# STM32C562 register map
File version: 2.1.0
CPU: CM33 r0p4, little endian, MPU, FPU, 4 interrupt priority bits
Registers are 32-bit, read-write, reset 0x0 unless marked. A register's access mark holds for its fields unless they carry their own. Offsets are from the block's base; [hi:lo] are bit positions; {n}, {i} and the like mark numbered series; 'fields as' and 'values as' point back to an identical list.

## RAMCFG — RAMCFG address block description
Base 0x40026000
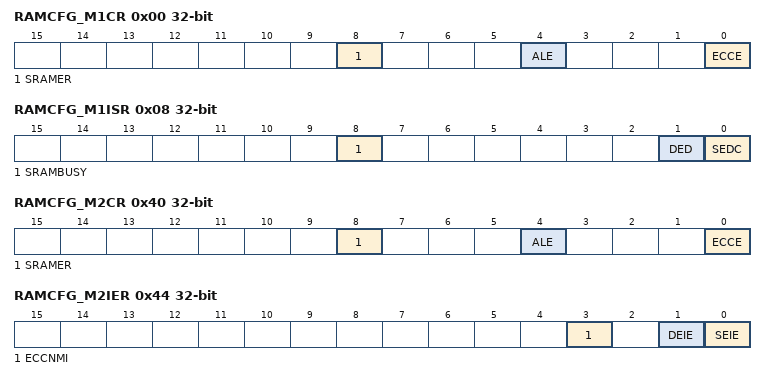
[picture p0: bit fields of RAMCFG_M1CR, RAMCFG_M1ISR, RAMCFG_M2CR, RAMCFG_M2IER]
0x00 RAMCFG_M1CR (reset mask 0xFFFFFFF0) — RAMCFG memory 1 control register
  [8] SRAMER — SRAM erase
    0=No erase operation on going; 1=Erase operation on going
  [4] ALE — Address latch enable
    0=Failing address not stored in the SRAMx ECC single/double error address registers; 1=Failing address stored in the SRAMx ECC single/double error address registers
  [0] ECCE — ECC enable.
    0=ECC disabled; 1=ECC enabled
0x08 RAMCFG_M1ISR ro — RAMCFG memory 1 interrupt status register
  [8] SRAMBUSY — SRAM busy with erase operation
    0=No erase operation on going; 1=Erase operation on going
  [1] DED — ECC double error detected
    0=No double error; 1=Double error detected
  [0] SEDC — ECC single error detected and corrected
    0=No single error; 1=Single error detected and corrected
0x28 RAMCFG_M1ERKEYR wo — RAMCFG memory 1 erase key register
  [7:0] ERASEKEY — Erase write protection key
0x40 RAMCFG_M2CR (reset mask 0xFFFFFFF0) — RAMCFG memory 2 control register
  fields as RAMCFG_M1CR
0x44 RAMCFG_M2IER — RAMCFG memory 2 interrupt enable register
  [3] ECCNMI — Double error NMI
    0=NMI not generated in case of ECC double error; 1=NMI generated in case of ECC double error
  [1] DEIE — ECC double error interrupt enable
    0=Double error interrupt disabled; 1=Double error interrupt enabled
  [0] SEIE — ECC single error interrupt enable
    0=Single error interrupt disabled; 1=Single error interrupt enabled
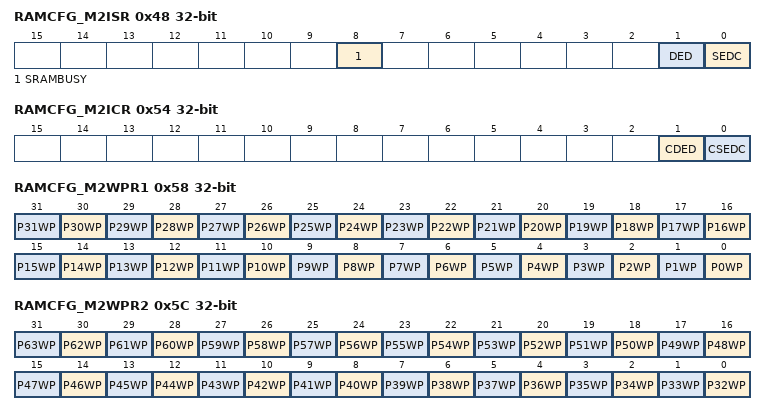
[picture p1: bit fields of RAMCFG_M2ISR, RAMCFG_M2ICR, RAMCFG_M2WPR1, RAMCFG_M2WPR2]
0x48 RAMCFG_M2ISR ro — RAMCFG memory 2 interrupt status register
  fields as RAMCFG_M1ISR
0x4C RAMCFG_M2SEAR ro — RAMCFG memory 2 ECC single error address register
  [31:0] ESEA — ECC single error address
0x50 RAMCFG_M2DEAR ro — RAMCFG memory 2 ECC double error address register
  [31:0] EDEA — ECC double error address
0x54 RAMCFG_M2ICR — RAMCFG memory 2 interrupt clear register 2
  [1] CDED — Clear ECC double error detected
  [0] CSEDC — Clear ECC single error detected and corrected
0x58 RAMCFG_M2WPR1 — RAMCFG memory 2 write protection register 1
  [all] fields
    0=Write protection of SRAM2 1-Kbyte page y is disabled; 1=Write protection of SRAM2 1-Kbyte page y is enabled
  [n] P{n}WP (n=0..31) — SRAM2 1-Kbyte page y write protection
0x5C RAMCFG_M2WPR2 — RAMCFG memory 2 write protection register 2
  [all] fields
    values as the fields of RAMCFG_M2WPR1
  [n-32] P{n}WP (n=32..63) — SRAM2 1-Kbyte page y write protection
0x64 RAMCFG_M2ECCKEYR wo — RAMCFG memory 2 ECC key register
  [7:0] ECCKEY — ECC write protection key
0x68 RAMCFG_M2ERKEYR wo — RAMCFG memory 2 erase key register
  [7:0] ERASEKEY — Erase write protection key

## SBS — SBS address block description
Base 0x44000400
0x10 SBS_HDPLCR reset 0xB4 — SBS temporal isolation control register
  [7:0] INCR_HDPL — increment HDPL value
    180=no increment; 106=recommended value to increment HDPL level by one
0x14 SBS_HDPLSR ro reset not defined — SBS temporal isolation status register
  [7:0] HDPL — temporal isolation level
    81=HDPL1, hide protection level to be used to execute and protect an immutable root of trust (IROT) stage; 138=HDPL2, hide protection level to be used to execute and protect an updatable Root of Trust (UROT) stage; 111=HDPL3, hide protection level to be used to execute the application
0x104 SBS_FPUIMR reset 0x1F — SBS FPU interrupt mask register
  [5:0] FPU_IE — FPU interrupt enable
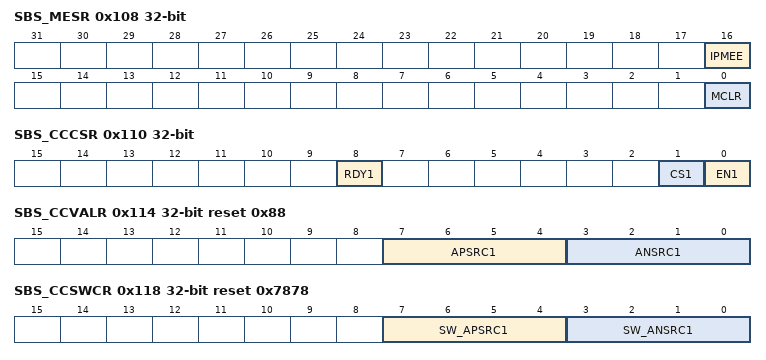
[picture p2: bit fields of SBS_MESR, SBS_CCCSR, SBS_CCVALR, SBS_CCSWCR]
0x108 SBS_MESR (reset mask 0xFFF0FFF0) — SBS memory erase status register
  [16] IPMEE — ICACHE erase status
    0=ICACHE erase ongoing; 1=ICACHE erase ended
  [0] MCLR — Device memories erase status
    0=memory erase ongoing if not yet cleared by software; 1=memory erase done
0x110 SBS_CCCSR — SBS compensation cell for I/Os control and status register
  [8] RDY1 ro — VDDIO compensation cell ready flag
    0=VDDIO compensation cell not ready; 1=VDDIO compensation cell ready (code value provided by the cell can be used)
  [1] CS1 — code selection for VDDIO power rail (reset value set to 1)
    0=Code from the cell (available in the SBS_CCVR); 1=Code from SBS_CCCR
  [0] EN1 — enable compensation cell for VDDIO power rail
    0=I/O compensation cell disabled; 1=I/O compensation cell enabled
0x114 SBS_CCVALR ro reset 0x88 — SBS compensation cell for I/Os value register
  [7:4] APSRC1 — compensation value for the PMOS transistor
  [3:0] ANSRC1 — compensation value for the NMOS transistor
0x118 SBS_CCSWCR reset 0x7878 — SBS compensation cell for I/Os software code register
  [7:4] SW_APSRC1 — PMOS compensation code for the VDD power rails
  [3:0] SW_ANSRC1 — NMOS compensation code for VDD power rails
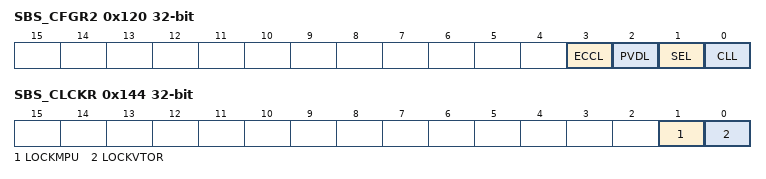
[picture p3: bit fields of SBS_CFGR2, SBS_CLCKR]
0x120 SBS_CFGR2 — SBS Class B register
  [3] ECCL — ECC lock
    0=double ECC error flag disconnected to timer break inputs; 1=double ECC error flag connected to timer break inputs
  [2] PVDL — PVD lock
    0=PVD interrupt disconnected from timer break inputs; 1=PVD interrupt is connected to timer break inputs
  [1] SEL — SRAM ECC error lock
    0=SRAM double ECC error flag disconnected from timer break inputs; 1=SRAM double ECC error flag connected to timer break inputs
  [0] CLL — core lockup lock
    0=lockup output disconnected from timer break inputs; 1=lockup output connected to timer break inputs
0x144 SBS_CLCKR — SBS CPU lock register
  [1] LOCKMPU — MPU register lock
    0=MPU registers write enabled; 1=MPU registers write disabled
  [0] LOCKVTOR — VTOR register lock
    0=VTOR register write enabled; 1=VTOR register write disabled
0x14C SBS_ECCNMIR — SBS flift ECC NMI mask register
  [0] ECCNMI_MASK_EN — NMI behavior setup when a double ECC error occurs on FLITF data part
    0=NMI generated if a double ECC error in the FLITF data part; 1=NMI not generated if a double ECC error in the FLITF data part
